# STM32WL3R register map
File version: 1.0
CPU: CM0+ r0p0, little endian, MPU, no FPU, 4 interrupt priority bits
Registers are 32-bit, read-write, reset 0x0 unless marked. A register's access mark holds for its fields unless they carry their own. Offsets are from the block's base; [hi:lo] are bit positions; 'fields as' and 'values as' point back to an identical list.

## RTC — RTC address block description
Base 0x40004000
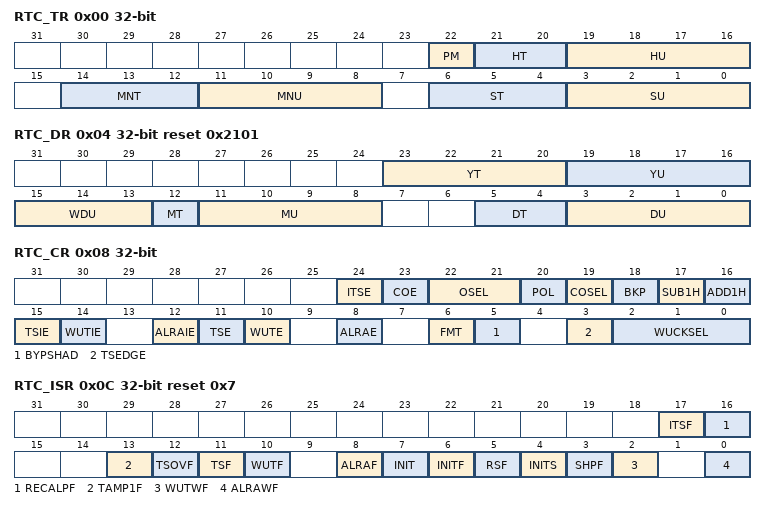
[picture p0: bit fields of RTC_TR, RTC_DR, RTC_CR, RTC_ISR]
0x00 RTC_TR
  [22] PM — AM/PM notation.
  [21:20] HT — Hour tens in BCD format.
  [19:16] HU — Hour units in BCD format.
  [14:12] MNT — Minute tens in BCD format.
  [11:8] MNU — Minute units in BCD format.
  [6:4] ST — Second tens in BCD format.
  [3:0] SU — Second units in BCD format.
0x04 RTC_DR reset 0x2101
  [23:20] YT — Year tens in BCD format.
  [19:16] YU — Year units in BCD format.
  [15:13] WDU — Week day units
  [12] MT — Month tens in BCD format.
  [11:8] MU — Month units in BCD format.
  [5:4] DT — Date tens in BCD format.
  [3:0] DU — Date units in BCD format.
0x08 RTC_CR
  [24] ITSE — Timestamp on internal event enable
  [23] COE — Calibration output enable
  [22:21] OSEL — Output selection
  [20] POL — Output polarity
  [19] COSEL — Calibration output selection
  [18] BKP — Backup
  [17] SUB1H wo — Subtract 1 hour (winter time change)
  [16] ADD1H wo — Add 1 hour (summer time change)
  [15] TSIE — Time-stamp interrupt enable
    0=Time-stamp Interrupt disable; 1=Time-stamp Interrupt enable
  [14] WUTIE — Wakeup timer interrupt enable
  [12] ALRAIE — Alarm A interrupt enable
  [11] TSE — Timestamp enable
  [10] WUTE — Wakeup timer enable
  [8] ALRAE — Alarm A enable
  [6] FMT — Hour format
    0=24 hour/day format; 1=AM/PM hour format
  [5] BYPSHAD — Bypass the shadow registers
  [3] TSEDGE — Time-stamp event active edge
  [2:0] WUCKSEL — Wakeup clock selection
0x0C RTC_ISR reset 0x7
  [17] ITSF — Internal time-stamp flag
  [16] RECALPF — Recalibration pending Flag
  [13] TAMP1F — RTC_TAMP1 detection flag
  [12] TSOVF — This flag is set by hardware when a time-stamp event occurs while TSF is already set.
  [11] TSF — This flag is set by hardware when a time-stamp event occurs.
  [10] WUTF — Wakeup timer flag
  [8] ALRAF — Alarm A flag
  [7] INIT — Initialization mode
  [6] INITF — Initialization flag
  [5] RSF — Registers synchronization flag
  [4] INITS — Initialization status flag
  [3] SHPF — Shift operation pending
  [2] WUTWF — Wakeup timer write flag
  [0] ALRAWF — Alarm A write flag
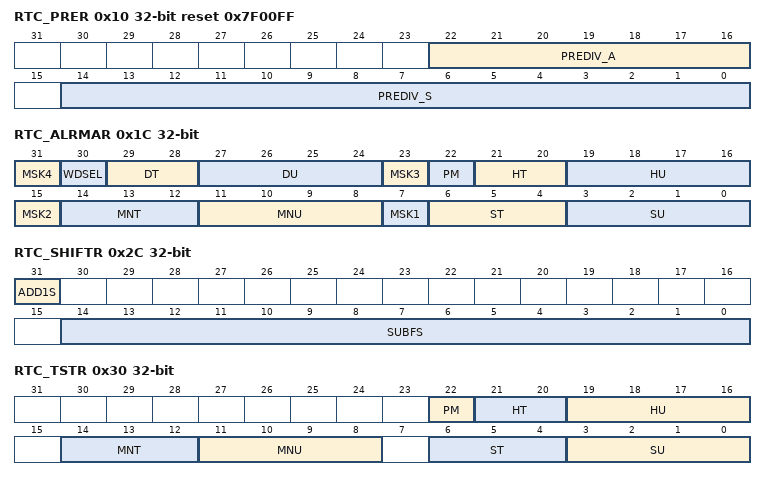
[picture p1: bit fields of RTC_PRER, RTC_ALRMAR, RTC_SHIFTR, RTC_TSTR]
0x10 RTC_PRER reset 0x7F00FF
  [22:16] PREDIV_A — Asynchronous prescaler factor
  [14:0] PREDIV_S — Synchronous prescaler factor
0x14 RTC_WUTR reset 0xFFFF
  [15:0] WUT — Wakeup auto-reload value bits
0x1C RTC_ALRMAR
  [31] MSK4 — Alarm A date mask
  [30] WDSEL — Week day selection
  [29:28] DT — Date tens in BCD format.
  [27:24] DU — Date units or day in BCD format.
  [23] MSK3 — Alarm A hours mask
  [22] PM — AM/PM notation
  [21:20] HT — Hour tens in BCD format.
  [19:16] HU — Hour units in BCD format.
  [15] MSK2 — Alarm A minutes mask
  [14:12] MNT — Minute tens in BCD format.
  [11:8] MNU — Minute units in BCD format.
  [7] MSK1 — Alarm A seconds mask
  [6:4] ST — Second tens in BCD format.
  [3:0] SU — Second units in BCD format.
0x24 RTC_WPR
  [7:0] KEY wo — Write protection key
0x28 RTC_SSR ro
  [15:0] SS — Sub second value
0x2C RTC_SHIFTR
  [31] ADD1S wo — Add one second
  [14:0] SUBFS wo — Subtract a fraction of a second
0x30 RTC_TSTR
  [22] PM — AM/PM notation
  [21:20] HT — Hour tens in BCD format.
  [19:16] HU — Hour units in BCD format.
  [14:12] MNT — Minute tens in BCD format.
  [11:8] MNU — Minute units in BCD format.
  [6:4] ST — Second tens in BCD format.
  [3:0] SU — Second units in BCD format.
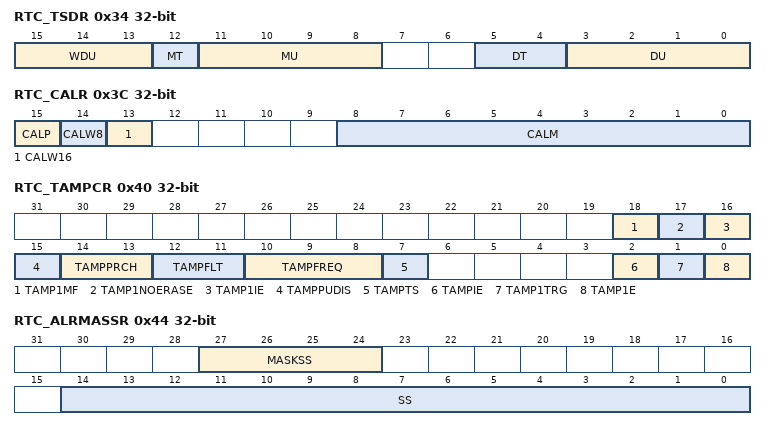
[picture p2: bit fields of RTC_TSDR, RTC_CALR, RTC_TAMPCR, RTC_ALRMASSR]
0x34 RTC_TSDR
  [15:13] WDU — Week day units
  [12] MT — Month tens in BCD format.
  [11:8] MU — Month units in BCD format.
  [5:4] DT — Date tens in BCD format.
  [3:0] DU — Date units in BCD format.
0x38 RTC_TSSSR ro
  [15:0] SS — Sub second value
0x3C RTC_CALR
  [15] CALP — Increase frequency of RTC by 488.
  [14] CALW8 — Use an 8-second calibration cycle period
  [13] CALW16 — Use a 16-second calibration cycle period
  [8:0] CALM — Calibration minus
0x40 RTC_TAMPCR
  [18] TAMP1MF — Tamper 1 mask flag
  [17] TAMP1NOERASE — Tamper 1 no erase
  [16] TAMP1IE — Tamper 1 interrupt enable
  [15] TAMPPUDIS — RTC_TAMPx pull-up disable
  [14:13] TAMPPRCH — RTC_TAMPx precharge duration
  [12:11] TAMPFLT — RTC_TAMPx filter count
  [10:8] TAMPFREQ — Tamper sampling frequency
  [7] TAMPTS — Activate timestamp on tamper detection event
  [2] TAMPIE — Tamper interrupt enable
  [1] TAMP1TRG — Active level for RTC_TAMP1 input
  [0] TAMP1E — RTC_TAMP1 input detection enable
0x44 RTC_ALRMASSR
  [27:24] MASKSS — Mask the most-significant bits starting at this bit
  [14:0] SS — Sub seconds value
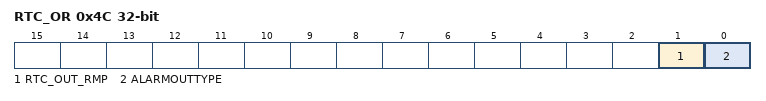
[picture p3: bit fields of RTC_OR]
0x4C RTC_OR
  [1] RTC_OUT_RMP — RTC_OUT remap
  [0] ALARMOUTTYPE — RTC_ALARM on PA8 output type
    0=RTC_ALARM, when mapped on PA8, is open-drain output; 1=RTC_ALARM, when mapped on PA8, is push-pull output
0x50 RTC_BKP0R — RTC_BKPxR register
  [31:0] BKP — The application can write or read data to and from these registers.
0x54 RTC_BKP1R — RTC_BKPxR register
  fields as RTC_BKP0R
